# ATmega32 device description
Architecture: AVR8; Family: megaAVR
Registers are 8-bit, access not given, no defined reset value unless marked. A register's access mark holds for its fields unless they carry their own. Offsets are from the block's base; [hi:lo] are bit positions; 'fields as' and 'values as' point back to an identical list.

## ADC — Analog-to-Digital Converter
Instances: ADC 0x00
0x24 ADC 16-bit — ADC Data Register Bytes
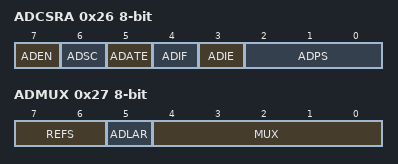
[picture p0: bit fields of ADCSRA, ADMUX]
0x26 ADCSRA — The ADC Control and Status register
  [7] ADEN — ADC Enable
  [6] ADSC — ADC Start Conversion
  [5] ADATE — ADC Auto Trigger
  [4] ADIF — ADC Interrupt Flag
  [3] ADIE — ADC Interrupt Enable
  [2:0] ADPS — ADC Prescaler Select Bits
    0=2; 1=2; 2=4; 3=8; 4=16; 5=32; 6=64; 7=128
0x27 ADMUX — The ADC multiplexer Selection Register
  [7:6] REFS — Reference Selection Bits
    0=AREF, Internal Vref turned off; 1=AVCC with external capacitor at AREF pin; 3=Internal 2.56V Voltage Reference with external capacitor at AREF pin
  [5] ADLAR — Left Adjust Result
  [4:0] MUX — Analog Channel and Gain Selection Bits
0x50 SFIOR — Special Function IO Register
  [7:5] ADTS — ADC Auto Trigger Sources

## PORTA — I/O Port
Instances: PORTA 0x00
0x39 PINA — Port A Input Pins
0x3A DDRA — Port A Data Direction Register
0x3B PORTA — Port A Data Register

## PORTB — I/O Port
Instances: PORTB 0x00
0x36 PINB — Port B Input Pins
0x37 DDRB — Port B Data Direction Register
0x38 PORTB — Port B Data Register

## PORTC — I/O Port
Instances: PORTC 0x00
0x33 PINC — Port C Input Pins
0x34 DDRC — Port C Data Direction Register
0x35 PORTC — Port C Data Register

## PORTD — I/O Port
Instances: PORTD 0x00
0x30 PIND — Port D Input Pins
0x31 DDRD — Port D Data Direction Register
0x32 PORTD — Port D Data Register

## CPU — CPU Registers
Instances: CPU 0x00
Parameters: CORE_VERSION=V2E
0x50 SFIOR bits used 2:0 — Special Function IO Register
0x51 OSCCAL — Oscillator Calibration Value
  [7:0] OSCCAL — Oscillator Calibration
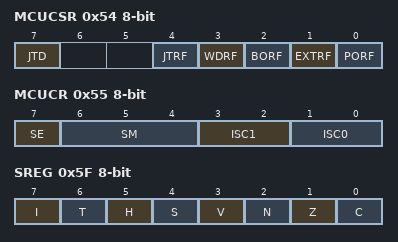
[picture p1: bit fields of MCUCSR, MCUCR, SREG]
0x54 MCUCSR — MCU Control And Status Register
  [7] JTD — JTAG Interface Disable
  [4] JTRF — JTAG Reset Flag
  [3] WDRF — Watchdog Reset Flag
  [2] BORF — Brown-out Reset Flag
  [1] EXTRF — External Reset Flag
  [0] PORF — Power-on reset flag
0x55 MCUCR — MCU Control Register
  [7] SE — Sleep Enable
  [6:4] SM — Sleep Mode Select
    0=IDLE; 1=ADC (ADC Noise Reduction (If Available)); 2=PDOWN (Power Down); 3=PSAVE (Power Save); 6=STDBY (Standby); 7=ESTDBY (Extended Standby)
  [3:2] ISC1 — Interrupt Sense Control 1 Bits
    0=Low Level of INTX; 1=Any Logical Change in INTX; 2=Falling Edge of INTX; 3=Rising Edge of INTX
  [1:0] ISC0 — Interrupt Sense Control 0 Bits
    values as ISC1
0x5D SP 16-bit bits used 11:0 — Stack Pointer
0x5F SREG — Status Register
  [7] I — Global Interrupt Enable
  [6] T — Bit Copy Storage
  [5] H — Half Carry Flag
  [4] S — Sign Bit
  [3] V — Two's Complement Overflow Flag
  [2] N — Negative Flag
  [1] Z — Zero Flag
  [0] C — Carry Flag
Value list OSCCAL_VALUE_ADDRESSES: 0=1_0_MHz; 1=2_0_MHz; 2=4_0_MHz; 3=8_0_MHz

## BOOT_LOAD — Bootloader
Instances: BOOT_LOAD 0x00
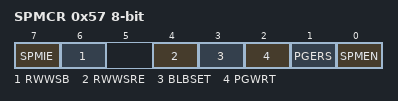
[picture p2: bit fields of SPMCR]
0x57 SPMCR — Store Program Memory Control Register
  [7] SPMIE — SPM Interrupt Enable
  [6] RWWSB — Read While Write Section Busy
  [4] RWWSRE — Read While Write secion read enable
  [3] BLBSET — Boot Lock Bit Set
  [2] PGWRT — Page Write
  [1] PGERS — Page Erase
  [0] SPMEN — Store Program Memory Enable

## TWI — Two Wire Serial Interface
Instances: TWI 0x00
0x20 TWBR — TWI Bit Rate register
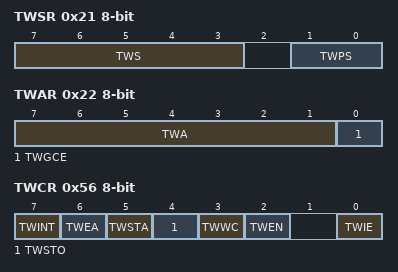
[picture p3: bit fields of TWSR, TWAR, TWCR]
0x21 TWSR — TWI Status Register
  [7:3] TWS (bit 3 of the value upward) — TWI Status
  [1:0] TWPS — TWI Prescaler bits
    0=1; 1=4; 2=16; 3=64
0x22 TWAR — TWI (Slave) Address register
  [7:1] TWA — TWI address bits
  [0] TWGCE — TWI general call recognition enable bit
0x23 TWDR — TWI Data register
0x56 TWCR — TWI Control Register
  [7] TWINT — TWI Interrupt Flag
  [6] TWEA — TWI Enable Acknowledge Bit
  [5] TWSTA — TWI Start Condition Bit
  [4] TWSTO — TWI Stop Condition Bit
  [3] TWWC — TWI Write Collition Flag
  [2] TWEN — TWI Enable Bit
  [0] TWIE — TWI Interrupt Enable
